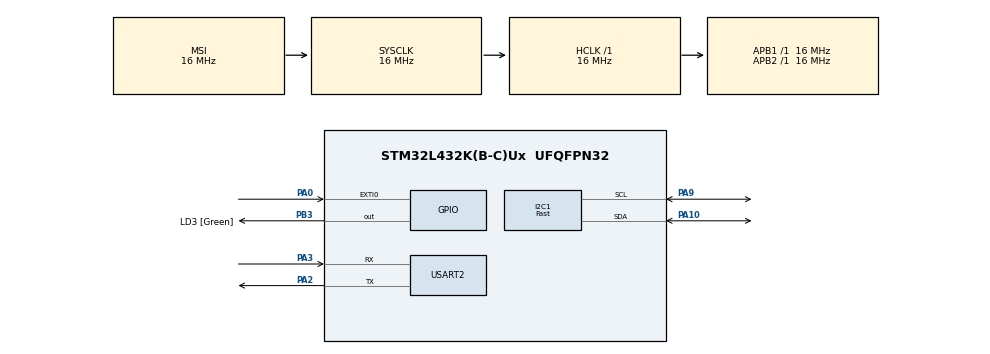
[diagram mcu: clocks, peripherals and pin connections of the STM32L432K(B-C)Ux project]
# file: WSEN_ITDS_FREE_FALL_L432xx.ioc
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I2C1.I2C_Speed_Mode=I2C_Fast
I2C1.Timing=0x0010061A
Mcu.Family=STM32L4
Mcu.Name=STM32L432K(B-C)Ux
Mcu.Package=UFQFPN32
NVIC.EXTI0_IRQn=true\:0\:0\:false\:false\:true\:true\:true
NVIC.PriorityGroup=NVIC_PRIORITYGROUP_4
PA0.GPIO_ModeDefaultEXTI=GPIO_MODE_IT_RISING_FALLING
PA0.Signal=GPXTI0
PA10.GPIO_Pu=GPIO_PULLUP
PA10.Mode=I2C
PA10.Signal=I2C1_SDA
PA13\ (JTMS-SWDIO).Mode=Serial_Wire
PA13\ (JTMS-SWDIO).Signal=SYS_JTMS-SWDIO
PA14\ (JTCK-SWCLK).Mode=Serial_Wire
PA14\ (JTCK-SWCLK).Signal=SYS_JTCK-SWCLK
PA2.Mode=Asynchronous
PA2.Signal=USART2_TX
PA3.Mode=Asynchronous
PA3.Signal=USART2_RX
PA9.GPIO_Pu=GPIO_PULLUP
PA9.Mode=I2C
PA9.Signal=I2C1_SCL
PB3\ (JTDO-TRACESWO).GPIO_Label=LD3 [Green]
PB3\ (JTDO-TRACESWO).Signal=GPIO_Output
ProjectManager.HeapSize=0x200
ProjectManager.StackSize=0x400
ProjectManager.TargetToolchain=STM32CubeIDE
RCC.ADCFreq_Value=64000000
RCC.AHBFreq_Value=16000000
RCC.APB1Freq_Value=16000000
RCC.APB1TimFreq_Value=16000000
RCC.APB2Freq_Value=16000000
RCC.APB2TimFreq_Value=16000000
RCC.CortexFreq_Value=16000000
RCC.HCLKFreq_Value=16000000
RCC.HSE_VALUE=8000000
RCC.HSI48_VALUE=48000000
RCC.HSI_VALUE=16000000
RCC.LSE_VALUE=32768
RCC.MSIClockRange=RCC_MSIRANGE_8
RCC.MSI_VALUE=16000000
RCC.SYSCLKFreq_VALUE=16000000
RCC.USBFreq_Value=64000000
RCC.VCOOutputFreq_Value=128000000
USART2.VirtualMode-Asynchronous=VM_ASYNC
board=custom

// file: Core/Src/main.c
/* USER CODE BEGIN Header */
/*
 ***************************************************************************************************
 * This file is part of Sensors SDK:
 * https://www.we-online.com/sensors, https://github.com/WurthElektronik/Sensors-SDK_STM32
 *
 * THE SOFTWARE INCLUDING THE SOURCE CODE IS PROVIDED “AS IS”. YOU ACKNOWLEDGE THAT WÜRTH ELEKTRONIK
 * EISOS MAKES NO REPRESENTATIONS AND WARRANTIES OF ANY KIND RELATED TO, BUT NOT LIMITED
 * TO THE NON-INFRINGEMENT OF THIRD PARTIES’ INTELLECTUAL PROPERTY RIGHTS OR THE
 * MERCHANTABILITY OR FITNESS FOR YOUR INTENDED PURPOSE OR USAGE. WÜRTH ELEKTRONIK EISOS DOES NOT
 * WARRANT OR REPRESENT THAT ANY LICENSE, EITHER EXPRESS OR IMPLIED, IS GRANTED UNDER ANY PATENT
 * RIGHT, COPYRIGHT, MASK WORK RIGHT, OR OTHER INTELLECTUAL PROPERTY RIGHT RELATING TO ANY
 * COMBINATION, MACHINE, OR PROCESS IN WHICH THE PRODUCT IS USED. INFORMATION PUBLISHED BY
 * WÜRTH ELEKTRONIK EISOS REGARDING THIRD-PARTY PRODUCTS OR SERVICES DOES NOT CONSTITUTE A LICENSE
 * FROM WÜRTH ELEKTRONIK EISOS TO USE SUCH PRODUCTS OR SERVICES OR A WARRANTY OR ENDORSEMENT
 * THEREOF
 *
 * THIS SOURCE CODE IS PROTECTED BY A LICENSE.
 * FOR MORE INFORMATION PLEASE CAREFULLY READ THE LICENSE AGREEMENT FILE (license_terms_wsen_sdk.pdf)
 * LOCATED IN THE ROOT DIRECTORY OF THIS DRIVER PACKAGE.
 *
 * COPYRIGHT (c) 2022 Würth Elektronik eiSos GmbH & Co. KG
 *
 ***************************************************************************************************
 */
/* USER CODE END Header */
#include "main.h"
#include "i2c.h"
#include "usart.h"
#include "gpio.h"

/* USER CODE BEGIN Includes */

#include "examples/WSEN_ITDS_FREE_FALL/WSEN_ITDS_FREE_FALL_EXAMPLE.h"

/* USER CODE END Includes */

void SystemClock_Config(void);

int main(void)
{

  /* MCU Configuration--------------------------------------------------------*/

  /* Reset of all peripherals, Initializes the Flash interface and the Systick. */
  HAL_Init();

  /* Configure the system clock */
  SystemClock_Config();

  /* Initialize all configured peripherals */
  MX_GPIO_Init();
  MX_I2C1_Init();
  MX_USART2_UART_Init();
  /* USER CODE BEGIN 2 */

  WE_itdsFreeFallExampleInit();

  /* USER CODE END 2 */

  /* Infinite loop */
  while (1)
  {

    /* USER CODE BEGIN 3 */

    WE_itdsFreeFallExampleLoop();
  }
  /* USER CODE END 3 */
}

void SystemClock_Config(void)
{
  RCC_OscInitTypeDef RCC_OscInitStruct = {0};
  RCC_ClkInitTypeDef RCC_ClkInitStruct = {0};

  /** Configure the main internal regulator output voltage
  */
  if (HAL_PWREx_ControlVoltageScaling(PWR_REGULATOR_VOLTAGE_SCALE1) != HAL_OK)
  {
    Error_Handler();
  }
  /** Initializes the RCC Oscillators according to the specified parameters
  * in the RCC_OscInitTypeDef structure.
  */
  RCC_OscInitStruct.OscillatorType = RCC_OSCILLATORTYPE_MSI;
  RCC_OscInitStruct.MSIState = RCC_MSI_ON;
  RCC_OscInitStruct.MSICalibrationValue = 0;
  RCC_OscInitStruct.MSIClockRange = RCC_MSIRANGE_8;
  RCC_OscInitStruct.PLL.PLLState = RCC_PLL_NONE;
  if (HAL_RCC_OscConfig(&RCC_OscInitStruct) != HAL_OK)
  {
    Error_Handler();
  }
  /** Initializes the CPU, AHB and APB buses clocks
  */
  RCC_ClkInitStruct.ClockType = RCC_CLOCKTYPE_HCLK|RCC_CLOCKTYPE_SYSCLK
                              |RCC_CLOCKTYPE_PCLK1|RCC_CLOCKTYPE_PCLK2;
  RCC_ClkInitStruct.SYSCLKSource = RCC_SYSCLKSOURCE_MSI;
  RCC_ClkInitStruct.AHBCLKDivider = RCC_SYSCLK_DIV1;
  RCC_ClkInitStruct.APB1CLKDivider = RCC_HCLK_DIV1;
  RCC_ClkInitStruct.APB2CLKDivider = RCC_HCLK_DIV1;

  if (HAL_RCC_ClockConfig(&RCC_ClkInitStruct, FLASH_LATENCY_0) != HAL_OK)
  {
    Error_Handler();
  }
}

void Error_Handler(void)
{
  __disable_irq();
  while (1)
  {
  }
}

/************************ (C) COPYRIGHT STMicroelectronics *****END OF FILE****/
